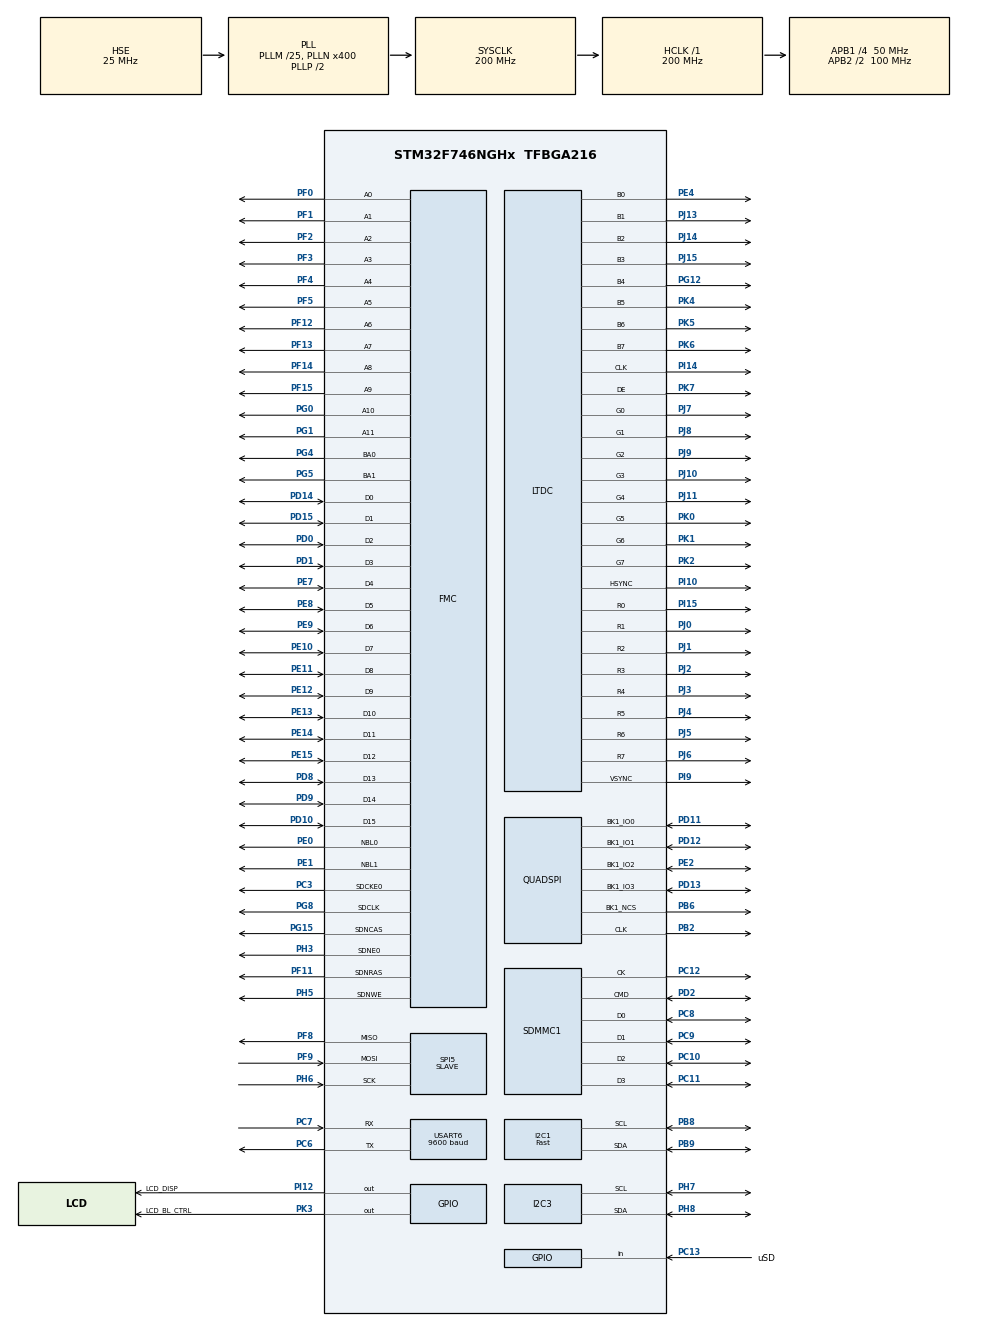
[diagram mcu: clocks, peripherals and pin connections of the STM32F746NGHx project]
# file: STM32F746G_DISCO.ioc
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CORTEX_M7.ART_ACCLERATOR_ENABLE=1
CORTEX_M7.AccessPermission-Cortex_Memory_Protection_Unit_Region0_Settings=MPU_REGION_FULL_ACCESS
CORTEX_M7.AccessPermission-Cortex_Memory_Protection_Unit_Region1_Settings=MPU_REGION_FULL_ACCESS
CORTEX_M7.BaseAddress-Cortex_Memory_Protection_Unit_Region0_Settings=0x00000000
CORTEX_M7.BaseAddress-Cortex_Memory_Protection_Unit_Region1_Settings=0x90000000
CORTEX_M7.CPU_DCache=Enabled
CORTEX_M7.CPU_ICache=Enabled
CORTEX_M7.Enable-Cortex_Memory_Protection_Unit_Region0_Settings=MPU_REGION_ENABLE
CORTEX_M7.Enable-Cortex_Memory_Protection_Unit_Region1_Settings=MPU_REGION_ENABLE
CORTEX_M7.IsCacheable-Cortex_Memory_Protection_Unit_Region1_Settings=MPU_ACCESS_CACHEABLE
CORTEX_M7.MPU_Control=MPU_PRIVILEGED_DEFAULT
CORTEX_M7.PREFETCH_ENABLE=1
CORTEX_M7.Size-Cortex_Memory_Protection_Unit_Region0_Settings=MPU_REGION_SIZE_256MB
CORTEX_M7.Size-Cortex_Memory_Protection_Unit_Region1_Settings=MPU_REGION_SIZE_16MB
Dma.Request0=SDMMC1_RX
Dma.Request1=SDMMC1_TX
Dma.Request2=SPI5_RX
Dma.Request3=USART6_RX
Dma.SDMMC1_RX.0.Direction=DMA_PERIPH_TO_MEMORY
Dma.SDMMC1_RX.0.FIFOMode=DMA_FIFOMODE_ENABLE
Dma.SDMMC1_RX.0.FIFOThreshold=DMA_FIFO_THRESHOLD_FULL
Dma.SDMMC1_RX.0.Instance=DMA2_Stream3
Dma.SDMMC1_RX.0.MemBurst=DMA_MBURST_INC4
Dma.SDMMC1_RX.0.MemDataAlignment=DMA_MDATAALIGN_WORD
Dma.SDMMC1_RX.0.MemInc=DMA_MINC_ENABLE
Dma.SDMMC1_RX.0.Mode=DMA_PFCTRL
Dma.SDMMC1_RX.0.PeriphBurst=DMA_PBURST_INC4
Dma.SDMMC1_RX.0.PeriphDataAlignment=DMA_PDATAALIGN_WORD
Dma.SDMMC1_RX.0.PeriphInc=DMA_PINC_DISABLE
Dma.SDMMC1_RX.0.Priority=DMA_PRIORITY_HIGH
Dma.SDMMC1_TX.1.Direction=DMA_MEMORY_TO_PERIPH
Dma.SDMMC1_TX.1.FIFOMode=DMA_FIFOMODE_ENABLE
Dma.SDMMC1_TX.1.FIFOThreshold=DMA_FIFO_THRESHOLD_FULL
Dma.SDMMC1_TX.1.Instance=DMA2_Stream6
Dma.SDMMC1_TX.1.MemBurst=DMA_MBURST_INC4
Dma.SDMMC1_TX.1.MemDataAlignment=DMA_MDATAALIGN_WORD
Dma.SDMMC1_TX.1.MemInc=DMA_MINC_ENABLE
Dma.SDMMC1_TX.1.Mode=DMA_PFCTRL
Dma.SDMMC1_TX.1.PeriphBurst=DMA_PBURST_INC4
Dma.SDMMC1_TX.1.PeriphDataAlignment=DMA_PDATAALIGN_WORD
Dma.SDMMC1_TX.1.PeriphInc=DMA_PINC_DISABLE
Dma.SDMMC1_TX.1.Priority=DMA_PRIORITY_HIGH
Dma.SPI5_RX.2.Direction=DMA_PERIPH_TO_MEMORY
Dma.SPI5_RX.2.FIFOMode=DMA_FIFOMODE_ENABLE
Dma.SPI5_RX.2.FIFOThreshold=DMA_FIFO_THRESHOLD_FULL
Dma.SPI5_RX.2.Instance=DMA2_Stream5
Dma.SPI5_RX.2.MemBurst=DMA_MBURST_SINGLE
Dma.SPI5_RX.2.MemDataAlignment=DMA_MDATAALIGN_BYTE
Dma.SPI5_RX.2.MemInc=DMA_MINC_ENABLE
Dma.SPI5_RX.2.Mode=DMA_CIRCULAR
Dma.SPI5_RX.2.PeriphBurst=DMA_PBURST_SINGLE
Dma.SPI5_RX.2.PeriphDataAlignment=DMA_PDATAALIGN_BYTE
Dma.SPI5_RX.2.PeriphInc=DMA_PINC_DISABLE
Dma.SPI5_RX.2.Priority=DMA_PRIORITY_LOW
Dma.USART6_RX.3.Direction=DMA_PERIPH_TO_MEMORY
Dma.USART6_RX.3.FIFOMode=DMA_FIFOMODE_ENABLE
Dma.USART6_RX.3.FIFOThreshold=DMA_FIFO_THRESHOLD_FULL
Dma.USART6_RX.3.Instance=DMA2_Stream1
Dma.USART6_RX.3.MemBurst=DMA_MBURST_SINGLE
Dma.USART6_RX.3.MemDataAlignment=DMA_MDATAALIGN_BYTE
Dma.USART6_RX.3.MemInc=DMA_MINC_ENABLE
Dma.USART6_RX.3.Mode=DMA_CIRCULAR
Dma.USART6_RX.3.PeriphBurst=DMA_PBURST_SINGLE
Dma.USART6_RX.3.PeriphDataAlignment=DMA_PDATAALIGN_BYTE
Dma.USART6_RX.3.PeriphInc=DMA_PINC_DISABLE
Dma.USART6_RX.3.Priority=DMA_PRIORITY_VERY_HIGH
FATFS.BSP.number=1
FATFS._MAX_SS=4096
FATFS0.BSP.STBoard=false
FATFS0.BSP.api=Unknown
FATFS0.BSP.instance=PC13
FATFS0.BSP.ip=GPIO
FATFS0.BSP.mode=Input
FATFS0.BSP.name=Detect_SDIO
FATFS0.BSP.solution=PC13
FMC.CASLatency1=FMC_SDRAM_CAS_LATENCY_3
FMC.ExitSelfRefreshDelay1=7
FMC.LoadToActiveDelay1=2
FMC.RCDDelay1=2
FMC.RPDelay1=2
FMC.ReadBurst1=FMC_SDRAM_RBURST_ENABLE
FMC.RowCycleDelay1=7
FMC.SDClockPeriod1=FMC_SDRAM_CLOCK_PERIOD_2
FMC.SelfRefreshTime1=4
FMC.WriteRecoveryTime1=3
FREERTOS.BinarySemaphores01=Uartsem,Static,UartsemControlBlock;SPIsem,Dynamic,NULL;SPIzap,Dynamic,NULL
FREERTOS.HEAP_NUMBER=4
FREERTOS.Mutexes01=myMutex01,Dynamic,NULL
FREERTOS.Tasks01=TouchGFXTask,24,4096,TouchGFX_Task,As weak,NULL,Dynamic,NULL,NULL;defaulttaks2,41,128,StartTask02,Default,NULL,Static,defaulttaks2Buffer,defaulttaks2ControlBlock;myTask03,42,128,StartTask03,Default,NULL,Static,myTask03Buffer,myTask03ControlBlock;UARTprzer,8,128,StartTask04,Default,NULL,Static,TaskDHBuffer,TaskDHControlBlock;TaskBMP,9,128,StartTask05,Default,NULL,Static,TaskBMPBuffer,TaskBMPControlBlock;SprawUART,10,128,StartTask06,Default,NULL,Static,SprawUARTBuffer,SprawUARTControlBlock;SPIprzerw,44,128,StartTask07,Default,NULL,Static,SPIprzerwBuffer,SPIprzerwControlBlock
FREERTOS.configCHECK_FOR_STACK_OVERFLOW=2
FREERTOS.configTOTAL_HEAP_SIZE=32768
FREERTOS.configUSE_APPLICATION_TASK_TAG=1
FREERTOS.configUSE_IDLE_HOOK=1
FREERTOS.configUSE_NEWLIB_REENTRANT=1
I2C1.I2C_Speed_Mode=I2C_Fast
I2C1.Timing=0x00401959
I2C3.Timing=0x00C0EAFF
LTDC.ActiveH=272
LTDC.ActiveW=480
LTDC.Alpha_L0=255
LTDC.FBStartAdress_L0=0xC0000000
LTDC.HBP=13
LTDC.HFP=32
LTDC.HSync=41
LTDC.ImageHeight_L0=272
LTDC.ImageWidth_L0=480
LTDC.Layers=0
LTDC.PixelFormat_L0=LTDC_PIXEL_FORMAT_RGB565
LTDC.VSync=10
LTDC.WindowX1_L0=480
LTDC.WindowY1_L0=272
Mcu.Family=STM32F7
Mcu.Name=STM32F746NGHx
Mcu.Package=TFBGA216
NVIC.DMA2D_IRQn=true\:5\:0\:true\:false\:true\:true\:true\:true\:true
NVIC.DMA2_Stream1_IRQn=true\:5\:0\:false\:false\:true\:true\:false\:true\:true
NVIC.DMA2_Stream3_IRQn=true\:5\:0\:true\:false\:true\:true\:false\:true\:true
NVIC.DMA2_Stream5_IRQn=true\:5\:0\:false\:false\:true\:true\:false\:true\:true
NVIC.DMA2_Stream6_IRQn=true\:5\:0\:true\:false\:true\:true\:false\:true\:true
NVIC.I2C1_ER_IRQn=true\:5\:0\:false\:false\:true\:true\:true\:true\:true
NVIC.I2C1_EV_IRQn=true\:5\:0\:false\:false\:true\:true\:true\:true\:true
NVIC.LTDC_IRQn=true\:5\:0\:true\:false\:true\:true\:true\:true\:true
NVIC.PriorityGroup=NVIC_PRIORITYGROUP_4
NVIC.SDMMC1_IRQn=true\:5\:0\:true\:false\:true\:true\:true\:true\:true
NVIC.SPI5_IRQn=true\:5\:0\:true\:false\:true\:true\:true\:true\:true
NVIC.TIM6_DAC_IRQn=true\:0\:0\:false\:false\:true\:false\:false\:true\:true
NVIC.TIM7_IRQn=true\:5\:0\:true\:false\:true\:true\:true\:true\:true
NVIC.TIM8_TRG_COM_TIM14_IRQn=true\:5\:0\:true\:false\:true\:true\:true\:true\:true
NVIC.TimeBase=TIM6_DAC_IRQn
NVIC.TimeBaseIP=TIM6
NVIC.USART6_IRQn=true\:5\:0\:true\:false\:true\:true\:true\:true\:true
PA13.Mode=Serial_Wire
PA13.Signal=SYS_JTMS-SWDIO
PA14.Mode=Serial_Wire
PA14.Signal=SYS_JTCK-SWCLK
PB2.Mode=Single Bank 1
PB2.Signal=QUADSPI_CLK
PB6.Mode=Single Bank 1
PB6.Signal=QUADSPI_BK1_NCS
PB8.Mode=I2C
PB8.Signal=I2C1_SCL
PB9.Mode=I2C
PB9.Signal=I2C1_SDA
PC10.Mode=SD_4_bits_Wide_bus
PC10.Signal=SDMMC1_D2
PC11.Mode=SD_4_bits_Wide_bus
PC11.Signal=SDMMC1_D3
PC12.Mode=SD_4_bits_Wide_bus
PC12.Signal=SDMMC1_CK
PC13.GPIO_Label=uSD
PC13.GPIO_PuPd=GPIO_NOPULL
PC13.Signal=GPIO_Input
PC3.Mode=SdramChipSelect1_1
PC3.Signal=FMC_SDCKE0
PC6.Mode=Asynchronous
PC6.Signal=USART6_TX
PC7.Mode=Asynchronous
PC7.Signal=USART6_RX
PC8.Mode=SD_4_bits_Wide_bus
PC8.Signal=SDMMC1_D0
PC9.Mode=SD_4_bits_Wide_bus
PC9.Signal=SDMMC1_D1
PD0.Signal=FMC_D2_DA2
PD1.Signal=FMC_D3_DA3
PD10.Signal=FMC_D15_DA15
PD11.Mode=Single Bank 1
PD11.Signal=QUADSPI_BK1_IO0
PD12.Mode=Single Bank 1
PD12.Signal=QUADSPI_BK1_IO1
PD13.Mode=Single Bank 1
PD13.Signal=QUADSPI_BK1_IO3
PD14.Signal=FMC_D0_DA0
PD15.Signal=FMC_D1_DA1
PD2.Mode=SD_4_bits_Wide_bus
PD2.Signal=SDMMC1_CMD
PD8.Signal=FMC_D13_DA13
PD9.Signal=FMC_D14_DA14
PE0.Signal=FMC_NBL0
PE1.Signal=FMC_NBL1
PE10.Signal=FMC_D7_DA7
PE11.Signal=FMC_D8_DA8
PE12.Signal=FMC_D9_DA9
PE13.Signal=FMC_D10_DA10
PE14.Signal=FMC_D11_DA11
PE15.Signal=FMC_D12_DA12
PE2.Mode=Single Bank 1
PE2.Signal=QUADSPI_BK1_IO2
PE4.Mode=RGB888
PE4.Signal=LTDC_B0
PE7.Signal=FMC_D4_DA4
PE8.Signal=FMC_D5_DA5
PE9.Signal=FMC_D6_DA6
PF0.Signal=FMC_A0
PF1.Signal=FMC_A1
PF11.Signal=FMC_SDNRAS
PF12.Signal=FMC_A6
PF13.Signal=FMC_A7
PF14.Signal=FMC_A8
PF15.Signal=FMC_A9
PF2.Signal=FMC_A2
PF3.Signal=FMC_A3
PF4.Signal=FMC_A4
PF5.Signal=FMC_A5
PF8.Mode=Full_Duplex_Slave
PF8.Signal=SPI5_MISO
PF9.Mode=Full_Duplex_Slave
PF9.Signal=SPI5_MOSI
PG0.Signal=FMC_A10
PG1.Signal=FMC_A11
PG12.Mode=RGB888
PG12.Signal=LTDC_B4
PG15.Signal=FMC_SDNCAS
PG4.Signal=FMC_A14_BA0
PG5.Signal=FMC_A15_BA1
PG8.Signal=FMC_SDCLK
PH0/OSC_IN.Mode=HSE-External-Oscillator
PH0/OSC_IN.Signal=RCC_OSC_IN
PH1/OSC_OUT.Mode=HSE-External-Oscillator
PH1/OSC_OUT.Signal=RCC_OSC_OUT
PH3.Mode=SdramChipSelect1_1
PH3.Signal=FMC_SDNE0
PH5.Signal=FMC_SDNWE
PH6.Mode=Full_Duplex_Slave
PH6.Signal=SPI5_SCK
PH7.Mode=I2C
PH7.Signal=I2C3_SCL
PH8.Mode=I2C
PH8.Signal=I2C3_SDA
PI10.Mode=RGB888
PI10.Signal=LTDC_HSYNC
PI12.GPIO_Label=LCD_DISP
PI12.PinState=GPIO_PIN_SET
PI12.Signal=GPIO_Output
PI14.Mode=RGB888
PI14.Signal=LTDC_CLK
PI15.Mode=RGB888
PI15.Signal=LTDC_R0
PI9.Mode=RGB888
PI9.Signal=LTDC_VSYNC
PJ0.Mode=RGB888
PJ0.Signal=LTDC_R1
PJ1.Mode=RGB888
PJ1.Signal=LTDC_R2
PJ10.Mode=RGB888
PJ10.Signal=LTDC_G3
PJ11.Mode=RGB888
PJ11.Signal=LTDC_G4
PJ13.Mode=RGB888
PJ13.Signal=LTDC_B1
PJ14.Mode=RGB888
PJ14.Signal=LTDC_B2
PJ15.Mode=RGB888
PJ15.Signal=LTDC_B3
PJ2.Mode=RGB888
PJ2.Signal=LTDC_R3
PJ3.Mode=RGB888
PJ3.Signal=LTDC_R4
PJ4.Mode=RGB888
PJ4.Signal=LTDC_R5
PJ5.Mode=RGB888
PJ5.Signal=LTDC_R6
PJ6.Mode=RGB888
PJ6.Signal=LTDC_R7
PJ7.Mode=RGB888
PJ7.Signal=LTDC_G0
PJ8.Mode=RGB888
PJ8.Signal=LTDC_G1
PJ9.Mode=RGB888
PJ9.Signal=LTDC_G2
PK0.Mode=RGB888
PK0.Signal=LTDC_G5
PK1.Mode=RGB888
PK1.Signal=LTDC_G6
PK2.Mode=RGB888
PK2.Signal=LTDC_G7
PK3.GPIO_Label=LCD_BL_CTRL
PK3.PinState=GPIO_PIN_SET
PK3.Signal=GPIO_Output
PK4.Mode=RGB888
PK4.Signal=LTDC_B5
PK5.Mode=RGB888
PK5.Signal=LTDC_B6
PK6.Mode=RGB888
PK6.Signal=LTDC_B7
PK7.Mode=RGB888
PK7.Signal=LTDC_DE
ProjectManager.HeapSize=0x400
ProjectManager.StackSize=0x800
ProjectManager.TargetToolchain=STM32CubeIDE
QUADSPI.ChipSelectHighTime=QSPI_CS_HIGH_TIME_6_CYCLE
QUADSPI.ClockPrescaler=1
QUADSPI.FifoThreshold=4
QUADSPI.FlashSize=24
QUADSPI.SampleShifting=QSPI_SAMPLE_SHIFTING_HALFCYCLE
RCC.AHBFreq_Value=200000000
RCC.APB1CLKDivider=RCC_HCLK_DIV4
RCC.APB1Freq_Value=50000000
RCC.APB1TimFreq_Value=100000000
RCC.APB2CLKDivider=RCC_HCLK_DIV2
RCC.APB2Freq_Value=100000000
RCC.APB2TimFreq_Value=200000000
RCC.CortexFreq_Value=200000000
RCC.HCLKFreq_Value=200000000
RCC.HSE_VALUE=25000000
RCC.HSI_VALUE=16000000
RCC.LSE_VALUE=32768
RCC.PLLI2SN=100
RCC.PLLM=25
RCC.PLLN=400
RCC.PLLQ=8
RCC.PLLSAIN=384
RCC.PLLSAIR=5
RCC.PLLSAIRDiv=RCC_PLLSAIDIVR_8
RCC.PLLSourceVirtual=RCC_PLLSOURCE_HSE
RCC.SDMMCClockSelection=RCC_SDMMC1CLKSOURCE_CLK48
RCC.SYSCLKFreq_VALUE=200000000
RCC.SYSCLKSource=RCC_SYSCLKSOURCE_PLLCLK
RCC.USBFreq_Value=50000000
RCC.VCOOutputFreq_Value=400000000
SH.FMC_A0.0=FMC_A0,12b-sda1
SH.FMC_A1.0=FMC_A1,12b-sda1
SH.FMC_A10.0=FMC_A10,12b-sda1
SH.FMC_A11.0=FMC_A11,12b-sda1
SH.FMC_A14_BA0.0=FMC_BA0,FourSdramBanks1
SH.FMC_A15_BA1.0=FMC_BA1,FourSdramBanks1
SH.FMC_A2.0=FMC_A2,12b-sda1
SH.FMC_A3.0=FMC_A3,12b-sda1
SH.FMC_A4.0=FMC_A4,12b-sda1
SH.FMC_A5.0=FMC_A5,12b-sda1
SH.FMC_A6.0=FMC_A6,12b-sda1
SH.FMC_A7.0=FMC_A7,12b-sda1
SH.FMC_A8.0=FMC_A8,12b-sda1
SH.FMC_A9.0=FMC_A9,12b-sda1
SH.FMC_D0_DA0.0=FMC_D0,sd-16b-d1
SH.FMC_D10_DA10.0=FMC_D10,sd-16b-d1
SH.FMC_D11_DA11.0=FMC_D11,sd-16b-d1
SH.FMC_D12_DA12.0=FMC_D12,sd-16b-d1
SH.FMC_D13_DA13.0=FMC_D13,sd-16b-d1
SH.FMC_D14_DA14.0=FMC_D14,sd-16b-d1
SH.FMC_D15_DA15.0=FMC_D15,sd-16b-d1
SH.FMC_D1_DA1.0=FMC_D1,sd-16b-d1
SH.FMC_D2_DA2.0=FMC_D2,sd-16b-d1
SH.FMC_D3_DA3.0=FMC_D3,sd-16b-d1
SH.FMC_D4_DA4.0=FMC_D4,sd-16b-d1
SH.FMC_D5_DA5.0=FMC_D5,sd-16b-d1
SH.FMC_D6_DA6.0=FMC_D6,sd-16b-d1
SH.FMC_D7_DA7.0=FMC_D7,sd-16b-d1
SH.FMC_D8_DA8.0=FMC_D8,sd-16b-d1
SH.FMC_D9_DA9.0=FMC_D9,sd-16b-d1
SH.FMC_NBL0.0=FMC_NBL0,Sd2ByteEnable1
SH.FMC_NBL1.0=FMC_NBL1,Sd2ByteEnable1
SH.FMC_SDCLK.0=FMC_SDCLK,12b-sda1
SH.FMC_SDNCAS.0=FMC_SDNCAS,12b-sda1
SH.FMC_SDNRAS.0=FMC_SDNRAS,12b-sda1
SH.FMC_SDNWE.0=FMC_SDNWE,12b-sda1
SPI5.DataSize=SPI_DATASIZE_8BIT
SPI5.Direction=SPI_DIRECTION_2LINES
SPI5.Mode=SPI_MODE_SLAVE
SPI5.VirtualType=VM_SLAVE
STMicroelectronics.X-CUBE-TOUCHGFX.4.21.0.ApplicationCcGraphicsJjApplication=TouchGFXOoGenerator
STMicroelectronics.X-CUBE-TOUCHGFX.4.21.0.tgfx_address1=0xC0000000
STMicroelectronics.X-CUBE-TOUCHGFX.4.21.0.tgfx_address2=0xC003FC00
STMicroelectronics.X-CUBE-TOUCHGFX.4.21.0.tgfx_buffering_strategy=Double
STMicroelectronics.X-CUBE-TOUCHGFX.4.21.0.tgfx_display_interface=disp_ltdc
STMicroelectronics.X-CUBE-TOUCHGFX.4.21.0.tgfx_hardware_accelerator=dma_2d
STMicroelectronics.X-CUBE-TOUCHGFX.4.21.0.tgfx_location=By Address
STMicroelectronics.X-CUBE-TOUCHGFX.4.21.0.tgfx_vsync=vsync_ltdc
TIM14.Period=40000
TIM14.Prescaler=9999
TIM7.Period=60000
TIM7.Prescaler=99
USART6.BaudRate=9600
USART6.VirtualMode-Asynchronous=VM_ASYNC
VP_CRC_VS_CRC.Mode=CRC_Activate
VP_DMA2D_VS_DMA2D.Mode=DMA2D_Activate
VP_FATFS_VS_SDIO.Mode=SDIO
VP_FREERTOS_VS_CMSIS_V2.Mode=CMSIS_V2
VP_RTC_VS_RTC_Activate.Mode=RTC_Enabled
VP_RTC_VS_RTC_Calendar.Mode=RTC_Calendar
VP_STMicroelectronics.X-CUBE-TOUCHGFX_VS_GraphicsJjApplication_4.21.0.Mode=GraphicsJjApplication
VP_SYS_VS_tim6.Mode=TIM6
VP_TIM14_VS_ClockSourceINT.Mode=Enable_Timer
VP_TIM7_VS_ClockSourceINT.Mode=Enable_Timer
board=custom

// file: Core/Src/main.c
/* USER CODE BEGIN Header */
/**
  ******************************************************************************
  * @file           : main.c
  * @brief          : Main program body
  ******************************************************************************
  * @attention
  *
  * <h2><center>&copy; Copyright (c) 2020 STMicroelectronics.
  * All rights reserved.</center></h2>
  *
  * This software component is licensed by ST under Ultimate Liberty license
  * SLA0044, the "License"; You may not use this file except in compliance with
  * the License. You may obtain a copy of the License at:
  *                             www.st.com/SLA0044
  *
  ******************************************************************************
  */
/* USER CODE END Header */
#include "main.h"
#include "cmsis_os.h"
#include "fatfs.h"
#include "app_touchgfx.h"

/* USER CODE BEGIN Includes */
#include <stm32746g_discovery_qspi.h>
#include <string.h>
#include <stdio.h>

#include "mpu6050.h"
#include "BMPXX80.h"
#include "DHT.h"
/* USER CODE END Includes */

typedef StaticTask_t osStaticThreadDef_t;
typedef StaticSemaphore_t osStaticSemaphoreDef_t;
/* USER CODE BEGIN PTD */
DHT_DataTypedef DHT11_Data;
MPU6050_t MPU6050;
RTC_TimeTypeDef RtcTime;
RTC_DateTypeDef RtcDate;
#define SPIbufor 8160
#define GPSbufor 1000
/* USER CODE END PTD */

/* USER CODE BEGIN PD */

#define REFRESH_COUNT        1835

#define SDRAM_TIMEOUT                            ((uint32_t)0xFFFF)
#define SDRAM_MODEREG_BURST_LENGTH_1             ((uint16_t)0x0000)
#define SDRAM_MODEREG_BURST_LENGTH_2             ((uint16_t)0x0001)
#define SDRAM_MODEREG_BURST_LENGTH_4             ((uint16_t)0x0002)
#define SDRAM_MODEREG_BURST_LENGTH_8             ((uint16_t)0x0004)
#define SDRAM_MODEREG_BURST_TYPE_SEQUENTIAL      ((uint16_t)0x0000)
#define SDRAM_MODEREG_BURST_TYPE_INTERLEAVED     ((uint16_t)0x0008)
#define SDRAM_MODEREG_CAS_LATENCY_2              ((uint16_t)0x0020)
#define SDRAM_MODEREG_CAS_LATENCY_3              ((uint16_t)0x0030)
#define SDRAM_MODEREG_OPERATING_MODE_STANDARD    ((uint16_t)0x0000)
#define SDRAM_MODEREG_WRITEBURST_MODE_PROGRAMMED ((uint16_t)0x0000)
#define SDRAM_MODEREG_WRITEBURST_MODE_SINGLE     ((uint16_t)0x0200)

/* USER CODE END PD */

CRC_HandleTypeDef hcrc;

DMA2D_HandleTypeDef hdma2d;

I2C_HandleTypeDef hi2c1;
I2C_HandleTypeDef hi2c3;

LTDC_HandleTypeDef hltdc;

QSPI_HandleTypeDef hqspi;

RTC_HandleTypeDef hrtc;

SD_HandleTypeDef hsd1;
DMA_HandleTypeDef hdma_sdmmc1_rx;
DMA_HandleTypeDef hdma_sdmmc1_tx;

SPI_HandleTypeDef hspi5;
DMA_HandleTypeDef hdma_spi5_rx;

TIM_HandleTypeDef htim7;
TIM_HandleTypeDef htim14;

UART_HandleTypeDef huart6;
DMA_HandleTypeDef hdma_usart6_rx;

SDRAM_HandleTypeDef hsdram1;

/* Definitions for TouchGFXTask */
osThreadId_t TouchGFXTaskHandle;
const osThreadAttr_t TouchGFXTask_attributes = {
  .name = "TouchGFXTask",
  .priority = (osPriority_t) osPriorityNormal,
  .stack_size = 4096 * 4
};
/* Definitions for defaulttaks2 */
osThreadId_t defaulttaks2Handle;
uint32_t defaulttaks2Buffer[ 128 ];
osStaticThreadDef_t defaulttaks2ControlBlock;
const osThreadAttr_t defaulttaks2_attributes = {
  .name = "defaulttaks2",
  .stack_mem = &defaulttaks2Buffer[0],
  .stack_size = sizeof(defaulttaks2Buffer),
  .cb_mem = &defaulttaks2ControlBlock,
  .cb_size = sizeof(defaulttaks2ControlBlock),
  .priority = (osPriority_t) osPriorityHigh1,
};
/* Definitions for myTask03 */
osThreadId_t myTask03Handle;
uint32_t myTask03Buffer[ 128 ];
osStaticThreadDef_t myTask03ControlBlock;
const osThreadAttr_t myTask03_attributes = {
  .name = "myTask03",
  .stack_mem = &myTask03Buffer[0],
  .stack_size = sizeof(myTask03Buffer),
  .cb_mem = &myTask03ControlBlock,
  .cb_size = sizeof(myTask03ControlBlock),
  .priority = (osPriority_t) osPriorityHigh2,
};
/* Definitions for UARTprzer */
osThreadId_t UARTprzerHandle;
uint32_t TaskDHBuffer[ 128 ];
osStaticThreadDef_t TaskDHControlBlock;
const osThreadAttr_t UARTprzer_attributes = {
  .name = "UARTprzer",
  .stack_mem = &TaskDHBuffer[0],
  .stack_size = sizeof(TaskDHBuffer),
  .cb_mem = &TaskDHControlBlock,
  .cb_size = sizeof(TaskDHControlBlock),
  .priority = (osPriority_t) osPriorityLow,
};
/* Definitions for TaskBMP */
osThreadId_t TaskBMPHandle;
uint32_t TaskBMPBuffer[ 128 ];
osStaticThreadDef_t TaskBMPControlBlock;
const osThreadAttr_t TaskBMP_attributes = {
  .name = "TaskBMP",
  .stack_mem = &TaskBMPBuffer[0],
  .stack_size = sizeof(TaskBMPBuffer),
  .cb_mem = &TaskBMPControlBlock,
  .cb_size = sizeof(TaskBMPControlBlock),
  .priority = (osPriority_t) osPriorityLow1,
};
/* Definitions for SprawUART */
osThreadId_t SprawUARTHandle;
uint32_t SprawUARTBuffer[ 128 ];
osStaticThreadDef_t SprawUARTControlBlock;
const osThreadAttr_t SprawUART_attributes = {
  .name = "SprawUART",
  .stack_mem = &SprawUARTBuffer[0],
  .stack_size = sizeof(SprawUARTBuffer),
  .cb_mem = &SprawUARTControlBlock,
  .cb_size = sizeof(SprawUARTControlBlock),
  .priority = (osPriority_t) osPriorityLow2,
};
/* Definitions for SPIprzerw */
osThreadId_t SPIprzerwHandle;
uint32_t SPIprzerwBuffer[ 128 ];
osStaticThreadDef_t SPIprzerwControlBlock;
const osThreadAttr_t SPIprzerw_attributes = {
  .name = "SPIprzerw",
  .stack_mem = &SPIprzerwBuffer[0],
  .stack_size = sizeof(SPIprzerwBuffer),
  .cb_mem = &SPIprzerwControlBlock,
  .cb_size = sizeof(SPIprzerwControlBlock),
  .priority = (osPriority_t) osPriorityHigh4,
};
/* Definitions for myMutex01 */
osMutexId_t myMutex01Handle;
const osMutexAttr_t myMutex01_attributes = {
  .name = "myMutex01"
};
/* Definitions for Uartsem */
osSemaphoreId_t UartsemHandle;
osStaticSemaphoreDef_t UartsemControlBlock;
const osSemaphoreAttr_t Uartsem_attributes = {
  .name = "Uartsem",
  .cb_mem = &UartsemControlBlock,
  .cb_size = sizeof(UartsemControlBlock),
};
/* Definitions for SPIsem */
osSemaphoreId_t SPIsemHandle;
const osSemaphoreAttr_t SPIsem_attributes = {
  .name = "SPIsem"
};
/* Definitions for SPIzap */
osSemaphoreId_t SPIzapHandle;
const osSemaphoreAttr_t SPIzap_attributes = {
  .name = "SPIzap"
};
/* USER CODE BEGIN PV */
static FMC_SDRAM_CommandTypeDef Command;

/* USER CODE END PV */

void SystemClock_Config(void);
static void MPU_Config(void);
static void MX_GPIO_Init(void);
static void MX_DMA_Init(void);
static void MX_DMA2D_Init(void);
static void MX_FMC_Init(void);
static void MX_I2C3_Init(void);
static void MX_LTDC_Init(void);
static void MX_QUADSPI_Init(void);
static void MX_SDMMC1_SD_Init(void);
static void MX_CRC_Init(void);
static void MX_TIM7_Init(void);
static void MX_I2C1_Init(void);
static void MX_SPI5_Init(void);
static void MX_TIM14_Init(void);
static void MX_RTC_Init(void);
static void MX_USART6_UART_Init(void);
void TouchGFX_Task(void *argument);
void StartTask02(void *argument);
void StartTask03(void *argument);
void StartTask04(void *argument);
void StartTask05(void *argument);
void StartTask06(void *argument);
void StartTask07(void *argument);

/* USER CODE BEGIN 0 */

/*Deklaracja funkcji odpowiedzialnej za odliczanie mikrosekund*/
void Delay_us (uint16_t us)
{
	__HAL_TIM_SET_COUNTER(&htim7,0);  // set the counter value a 0
	while ((__HAL_TIM_GET_COUNTER(&htim7)) < us);  // wait for the counter to reach the us input in the parameter
}

/*bufor do odbioru danych z kanału UART*/
uint8_t Received[GPSbufor] ;
/*kopia bufor do odbioru danych z kanału UART*/
uint8_t Received2[GPSbufor] ;
/*bufor dla danych o czasie zczytania danych*/
uint8_t Message[50];
/*bufor do odbioru danych z kanału SPI*/
uint8_t Received4[SPIbufor] ;
/*kopia bufora do odbioru danych z kanału SPI*/
uint8_t Received431[SPIbufor] ;
uint16_t Milliseconds;
/*kontrola wykonania polecenia {przerwanie_IT, przyrównanie do przerwania, iteracja co zaspis} dla SPI */
uint16_t asdUART1[3]={0,0,0};
/*kontrola wykonania polecenia {przerwanie_IT, przyrównanie do przerwania, iteracja co zaspis} dla UART */
uint16_t asdGPS[3]={0,0,0};
/*kontrola wykonania polecenia {przerwanie timera, iteracja co próbe zapisu , iteracja co kolejny pakiet bufora} dla SPI */
uint16_t asdCZUJNIKI[3]={0,0,0};
float TempDH, WilgDH;
float TempBMP;
int32_t CisnBMP;
/*zmienne do konwersji*/
int32_t  dod1;
int32_t  dod2;
int32_t  dod3;
int awaria=0;
/*bufor przechowujący dane do zapisu z czujników*/
char buffer[200][110];
/*licznik zapełnienia bufora*/
int licznik4=0;
int pomuart =0;

FRESULT res;
uint32_t byteswritten; /* licznik zapisanych danych */
/*zmienne odpowiedzialne za kontrole włączenia/wyłączenia zapisu */
int8_t zapisekran=0;
int8_t zapisdzial=0;

/* USER CODE END 0 */

int main(void)
{

  /* MPU Configuration--------------------------------------------------------*/
  MPU_Config();

  /* Enable I-Cache---------------------------------------------------------*/
  SCB_EnableICache();

  /* Enable D-Cache---------------------------------------------------------*/
  SCB_EnableDCache();

  /* MCU Configuration--------------------------------------------------------*/

  /* Reset of all peripherals, Initializes the Flash interface and the Systick. */
  HAL_Init();

  /* Configure the system clock */
  SystemClock_Config();

  /* Initialize all configured peripherals */
  MX_GPIO_Init();
  MX_DMA_Init();
  MX_DMA2D_Init();
  MX_FMC_Init();
  MX_I2C3_Init();
  MX_LTDC_Init();
  MX_QUADSPI_Init();
  MX_SDMMC1_SD_Init();
  MX_CRC_Init();
  MX_FATFS_Init();
  MX_TIM7_Init();
  MX_I2C1_Init();
  MX_SPI5_Init();
  MX_TIM14_Init();
  MX_RTC_Init();
  MX_USART6_UART_Init();
  MX_TouchGFX_Init();
  /* USER CODE BEGIN 2 */
  /* Call PreOsInit function */
  MX_TouchGFX_PreOSInit();

/*Inicjacja zegara odpowiedzialnego za liczenie mileskund */
  HAL_TIM_Base_Start_IT(&htim7);
  /*Inicjacja ustawień dla czujników */
  MPU6050_Init(&hi2c1, 1, 1, 5);
  MPU6050_Bypass(&hi2c1);
  HMC5883L_Setup(&hi2c1);
  MPU6050_Master(&hi2c1);
  MPU6050_Slave_Read(&hi2c1);
  BMP180_Init(&hi2c1,BMP180_STANDARD);

  /* USER CODE END 2 */

  /* Init scheduler */
  osKernelInitialize();
  /* Create the mutex(es) */
  /* creation of myMutex01 */
  myMutex01Handle = osMutexNew(&myMutex01_attributes);

  /* Create the semaphores(s) */
  /* creation of Uartsem */
  UartsemHandle = osSemaphoreNew(1, 1, &Uartsem_attributes);

  /* creation of SPIsem */
  SPIsemHandle = osSemaphoreNew(1, 1, &SPIsem_attributes);

  /* creation of SPIzap */
  SPIzapHandle = osSemaphoreNew(1, 1, &SPIzap_attributes);

  /* Create the thread(s) */
  /* creation of TouchGFXTask */
  TouchGFXTaskHandle = osThreadNew(TouchGFX_Task, NULL, &TouchGFXTask_attributes);

  /* creation of defaulttaks2 */
  defaulttaks2Handle = osThreadNew(StartTask02, NULL, &defaulttaks2_attributes);

  /* creation of myTask03 */
  myTask03Handle = osThreadNew(StartTask03, NULL, &myTask03_attributes);

  /* creation of UARTprzer */
  UARTprzerHandle = osThreadNew(StartTask04, NULL, &UARTprzer_attributes);

  /* creation of TaskBMP */
  TaskBMPHandle = osThreadNew(StartTask05, NULL, &TaskBMP_attributes);

  /* creation of SprawUART */
  SprawUARTHandle = osThreadNew(StartTask06, NULL, &SprawUART_attributes);

  /* creation of SPIprzerw */
  SPIprzerwHandle = osThreadNew(StartTask07, NULL, &SPIprzerw_attributes);

  /* Start scheduler */
  osKernelStart();

  /* We should never get here as control is now taken by the scheduler */
  /* Infinite loop */
  while (1)
  {

  }
}

void SystemClock_Config(void)
{
  RCC_OscInitTypeDef RCC_OscInitStruct = {0};
  RCC_ClkInitTypeDef RCC_ClkInitStruct = {0};
  RCC_PeriphCLKInitTypeDef PeriphClkInitStruct = {0};

  /** Configure the main internal regulator output voltage
  */
  __HAL_RCC_PWR_CLK_ENABLE();
  __HAL_PWR_VOLTAGESCALING_CONFIG(PWR_REGULATOR_VOLTAGE_SCALE1);
  /** Initializes the RCC Oscillators according to the specified parameters
  * in the RCC_OscInitTypeDef structure.
  */
  RCC_OscInitStruct.OscillatorType = RCC_OSCILLATORTYPE_LSI|RCC_OSCILLATORTYPE_HSE;
  RCC_OscInitStruct.HSEState = RCC_HSE_ON;
  RCC_OscInitStruct.LSIState = RCC_LSI_ON;
  RCC_OscInitStruct.PLL.PLLState = RCC_PLL_ON;
  RCC_OscInitStruct.PLL.PLLSource = RCC_PLLSOURCE_HSE;
  RCC_OscInitStruct.PLL.PLLM = 25;
  RCC_OscInitStruct.PLL.PLLN = 400;
  RCC_OscInitStruct.PLL.PLLP = RCC_PLLP_DIV2;
  RCC_OscInitStruct.PLL.PLLQ = 8;
  if (HAL_RCC_OscConfig(&RCC_OscInitStruct) != HAL_OK)
  {
    Error_Handler();
  }
  /** Activate the Over-Drive mode
  */
  if (HAL_PWREx_EnableOverDrive() != HAL_OK)
  {
    Error_Handler();
  }
  /** Initializes the CPU, AHB and APB buses clocks
  */
  RCC_ClkInitStruct.ClockType = RCC_CLOCKTYPE_HCLK|RCC_CLOCKTYPE_SYSCLK
                              |RCC_CLOCKTYPE_PCLK1|RCC_CLOCKTYPE_PCLK2;
  RCC_ClkInitStruct.SYSCLKSource = RCC_SYSCLKSOURCE_PLLCLK;
  RCC_ClkInitStruct.AHBCLKDivider = RCC_SYSCLK_DIV1;
  RCC_ClkInitStruct.APB1CLKDivider = RCC_HCLK_DIV4;
  RCC_ClkInitStruct.APB2CLKDivider = RCC_HCLK_DIV2;

  if (HAL_RCC_ClockConfig(&RCC_ClkInitStruct, FLASH_LATENCY_6) != HAL_OK)
  {
    Error_Handler();
  }
  PeriphClkInitStruct.PeriphClockSelection = RCC_PERIPHCLK_LTDC|RCC_PERIPHCLK_RTC
                              |RCC_PERIPHCLK_USART6|RCC_PERIPHCLK_I2C1
                              |RCC_PERIPHCLK_I2C3|RCC_PERIPHCLK_SDMMC1
                              |RCC_PERIPHCLK_CLK48;
  PeriphClkInitStruct.PLLSAI.PLLSAIN = 384;
  PeriphClkInitStruct.PLLSAI.PLLSAIR = 5;
  PeriphClkInitStruct.PLLSAI.PLLSAIQ = 2;
  PeriphClkInitStruct.PLLSAI.PLLSAIP = RCC_PLLSAIP_DIV2;
  PeriphClkInitStruct.PLLSAIDivQ = 1;
  PeriphClkInitStruct.PLLSAIDivR = RCC_PLLSAIDIVR_8;
  PeriphClkInitStruct.RTCClockSelection = RCC_RTCCLKSOURCE_LSI;
  PeriphClkInitStruct.Usart6ClockSelection = RCC_USART6CLKSOURCE_PCLK2;
  PeriphClkInitStruct.I2c1ClockSelection = RCC_I2C1CLKSOURCE_PCLK1;
  PeriphClkInitStruct.I2c3ClockSelection = RCC_I2C3CLKSOURCE_PCLK1;
  PeriphClkInitStruct.Clk48ClockSelection = RCC_CLK48SOURCE_PLL;
  PeriphClkInitStruct.Sdmmc1ClockSelection = RCC_SDMMC1CLKSOURCE_CLK48;
  if (HAL_RCCEx_PeriphCLKConfig(&PeriphClkInitStruct) != HAL_OK)
  {
    Error_Handler();
  }
}

static void MX_CRC_Init(void)
{

  hcrc.Instance = CRC;
  hcrc.Init.DefaultPolynomialUse = DEFAULT_POLYNOMIAL_ENABLE;
  hcrc.Init.DefaultInitValueUse = DEFAULT_INIT_VALUE_ENABLE;
  hcrc.Init.InputDataInversionMode = CRC_INPUTDATA_INVERSION_NONE;
  hcrc.Init.OutputDataInversionMode = CRC_OUTPUTDATA_INVERSION_DISABLE;
  hcrc.InputDataFormat = CRC_INPUTDATA_FORMAT_BYTES;
  if (HAL_CRC_Init(&hcrc) != HAL_OK)
  {
    Error_Handler();
  }

}

static void MX_DMA2D_Init(void)
{

  hdma2d.Instance = DMA2D;
  hdma2d.Init.Mode = DMA2D_M2M;
  hdma2d.Init.ColorMode = DMA2D_OUTPUT_ARGB8888;
  hdma2d.Init.OutputOffset = 0;
  hdma2d.LayerCfg[1].InputOffset = 0;
  hdma2d.LayerCfg[1].InputColorMode = DMA2D_INPUT_ARGB8888;
  hdma2d.LayerCfg[1].AlphaMode = DMA2D_NO_MODIF_ALPHA;
  hdma2d.LayerCfg[1].InputAlpha = 0;
  if (HAL_DMA2D_Init(&hdma2d) != HAL_OK)
  {
    Error_Handler();
  }
  if (HAL_DMA2D_ConfigLayer(&hdma2d, 1) != HAL_OK)
  {
    Error_Handler();
  }

}

static void MX_I2C1_Init(void)
{

  hi2c1.Instance = I2C1;
  hi2c1.Init.Timing = 0x00401959;
  hi2c1.Init.OwnAddress1 = 0;
  hi2c1.Init.AddressingMode = I2C_ADDRESSINGMODE_7BIT;
  hi2c1.Init.DualAddressMode = I2C_DUALADDRESS_DISABLE;
  hi2c1.Init.OwnAddress2 = 0;
  hi2c1.Init.OwnAddress2Masks = I2C_OA2_NOMASK;
  hi2c1.Init.GeneralCallMode = I2C_GENERALCALL_DISABLE;
  hi2c1.Init.NoStretchMode = I2C_NOSTRETCH_DISABLE;
  if (HAL_I2C_Init(&hi2c1) != HAL_OK)
  {
    Error_Handler();
  }
  /** Configure Analogue filter
  */
  if (HAL_I2CEx_ConfigAnalogFilter(&hi2c1, I2C_ANALOGFILTER_ENABLE) != HAL_OK)
  {
    Error_Handler();
  }
  /** Configure Digital filter
  */
  if (HAL_I2CEx_ConfigDigitalFilter(&hi2c1, 0) != HAL_OK)
  {
    Error_Handler();
  }

}

static void MX_I2C3_Init(void)
{

  hi2c3.Instance = I2C3;
  hi2c3.Init.Timing = 0x00C0EAFF;
  hi2c3.Init.OwnAddress1 = 0;
  hi2c3.Init.AddressingMode = I2C_ADDRESSINGMODE_7BIT;
  hi2c3.Init.DualAddressMode = I2C_DUALADDRESS_DISABLE;
  hi2c3.Init.OwnAddress2 = 0;
  hi2c3.Init.OwnAddress2Masks = I2C_OA2_NOMASK;
  hi2c3.Init.GeneralCallMode = I2C_GENERALCALL_DISABLE;
  hi2c3.Init.NoStretchMode = I2C_NOSTRETCH_DISABLE;
  if (HAL_I2C_Init(&hi2c3) != HAL_OK)
  {
    Error_Handler();
  }
  /** Configure Analogue filter
  */
  if (HAL_I2CEx_ConfigAnalogFilter(&hi2c3, I2C_ANALOGFILTER_ENABLE) != HAL_OK)
  {
    Error_Handler();
  }
  /** Configure Digital filter
  */
  if (HAL_I2CEx_ConfigDigitalFilter(&hi2c3, 0) != HAL_OK)
  {
    Error_Handler();
  }

}

static void MX_LTDC_Init(void)
{

  LTDC_LayerCfgTypeDef pLayerCfg = {0};

  hltdc.Instance = LTDC;
  hltdc.Init.HSPolarity = LTDC_HSPOLARITY_AL;
  hltdc.Init.VSPolarity = LTDC_VSPOLARITY_AL;
  hltdc.Init.DEPolarity = LTDC_DEPOLARITY_AL;
  hltdc.Init.PCPolarity = LTDC_PCPOLARITY_IPC;
  hltdc.Init.HorizontalSync = 40;
  hltdc.Init.VerticalSync = 9;
  hltdc.Init.AccumulatedHBP = 53;
  hltdc.Init.AccumulatedVBP = 11;
  hltdc.Init.AccumulatedActiveW = 533;
  hltdc.Init.AccumulatedActiveH = 283;
  hltdc.Init.TotalWidth = 565;
  hltdc.Init.TotalHeigh = 285;
  hltdc.Init.Backcolor.Blue = 0;
  hltdc.Init.Backcolor.Green = 0;
  hltdc.Init.Backcolor.Red = 0;
  if (HAL_LTDC_Init(&hltdc) != HAL_OK)
  {
    Error_Handler();
  }
  pLayerCfg.WindowX0 = 0;
  pLayerCfg.WindowX1 = 480;
  pLayerCfg.WindowY0 = 0;
  pLayerCfg.WindowY1 = 272;
  pLayerCfg.PixelFormat = LTDC_PIXEL_FORMAT_RGB565;
  pLayerCfg.Alpha = 255;
  pLayerCfg.Alpha0 = 0;
  pLayerCfg.BlendingFactor1 = LTDC_BLENDING_FACTOR1_CA;
  pLayerCfg.BlendingFactor2 = LTDC_BLENDING_FACTOR2_CA;
  pLayerCfg.FBStartAdress = 0xC0000000;
  pLayerCfg.ImageWidth = 480;
  pLayerCfg.ImageHeight = 272;
  pLayerCfg.Backcolor.Blue = 0;
  pLayerCfg.Backcolor.Green = 0;
  pLayerCfg.Backcolor.Red = 0;
  if (HAL_LTDC_ConfigLayer(&hltdc, &pLayerCfg, 0) != HAL_OK)
  {
    Error_Handler();
  }

}

static void MX_QUADSPI_Init(void)
{

  /* QUADSPI parameter configuration*/
  hqspi.Instance = QUADSPI;
  hqspi.Init.ClockPrescaler = 1;
  hqspi.Init.FifoThreshold = 4;
  hqspi.Init.SampleShifting = QSPI_SAMPLE_SHIFTING_HALFCYCLE;
  hqspi.Init.FlashSize = 24;
  hqspi.Init.ChipSelectHighTime = QSPI_CS_HIGH_TIME_6_CYCLE;
  hqspi.Init.ClockMode = QSPI_CLOCK_MODE_0;
  hqspi.Init.FlashID = QSPI_FLASH_ID_1;
  hqspi.Init.DualFlash = QSPI_DUALFLASH_DISABLE;
  if (HAL_QSPI_Init(&hqspi) != HAL_OK)
  {
    Error_Handler();
  }
  /* USER CODE BEGIN QUADSPI_Init 2 */
  BSP_QSPI_Init();

  BSP_QSPI_MemoryMappedMode();
  HAL_NVIC_DisableIRQ(QUADSPI_IRQn);
  /* USER CODE END QUADSPI_Init 2 */

}

static void MX_RTC_Init(void)
{

  RTC_TimeTypeDef sTime = {0};
  RTC_DateTypeDef sDate = {0};

  /** Initialize RTC Only
  */
  hrtc.Instance = RTC;
  hrtc.Init.HourFormat = RTC_HOURFORMAT_24;
  hrtc.Init.AsynchPrediv = 127;
  hrtc.Init.SynchPrediv = 255;
  hrtc.Init.OutPut = RTC_OUTPUT_DISABLE;
  hrtc.Init.OutPutPolarity = RTC_OUTPUT_POLARITY_HIGH;
  hrtc.Init.OutPutType = RTC_OUTPUT_TYPE_OPENDRAIN;
  if (HAL_RTC_Init(&hrtc) != HAL_OK)
  {
    Error_Handler();
  }

  /** Initialize RTC and set the Time and Date
  */
  sTime.Hours = 0x0;
  sTime.Minutes = 0x0;
  sTime.Seconds = 0x0;
  sTime.DayLightSaving = RTC_DAYLIGHTSAVING_NONE;
  sTime.StoreOperation = RTC_STOREOPERATION_RESET;
  if (HAL_RTC_SetTime(&hrtc, &sTime, RTC_FORMAT_BCD) != HAL_OK)
  {
    Error_Handler();
  }
  sDate.WeekDay = RTC_WEEKDAY_MONDAY;
  sDate.Month = RTC_MONTH_JANUARY;
  sDate.Date = 0x1;
  sDate.Year = 0x0;

  if (HAL_RTC_SetDate(&hrtc, &sDate, RTC_FORMAT_BCD) != HAL_OK)
  {
    Error_Handler();
  }

}

static void MX_SDMMC1_SD_Init(void)
{

  hsd1.Instance = SDMMC1;
  hsd1.Init.ClockEdge = SDMMC_CLOCK_EDGE_RISING;
  hsd1.Init.ClockBypass = SDMMC_CLOCK_BYPASS_DISABLE;
  hsd1.Init.ClockPowerSave = SDMMC_CLOCK_POWER_SAVE_DISABLE;
  hsd1.Init.BusWide = SDMMC_BUS_WIDE_1B;
  hsd1.Init.HardwareFlowControl = SDMMC_HARDWARE_FLOW_CONTROL_DISABLE;
  hsd1.Init.ClockDiv = 0;

}

static void MX_SPI5_Init(void)
{

  /* SPI5 parameter configuration*/
  hspi5.Instance = SPI5;
  hspi5.Init.Mode = SPI_MODE_SLAVE;
  hspi5.Init.Direction = SPI_DIRECTION_2LINES;
  hspi5.Init.DataSize = SPI_DATASIZE_8BIT;
  hspi5.Init.CLKPolarity = SPI_POLARITY_LOW;
  hspi5.Init.CLKPhase = SPI_PHASE_1EDGE;
  hspi5.Init.NSS = SPI_NSS_SOFT;
  hspi5.Init.FirstBit = SPI_FIRSTBIT_MSB;
  hspi5.Init.TIMode = SPI_TIMODE_DISABLE;
  hspi5.Init.CRCCalculation = SPI_CRCCALCULATION_DISABLE;
  hspi5.Init.CRCPolynomial = 7;
  hspi5.Init.CRCLength = SPI_CRC_LENGTH_DATASIZE;
  hspi5.Init.NSSPMode = SPI_NSS_PULSE_DISABLE;
  if (HAL_SPI_Init(&hspi5) != HAL_OK)
  {
    Error_Handler();
  }

}

static void MX_TIM7_Init(void)
{

  TIM_MasterConfigTypeDef sMasterConfig = {0};

  htim7.Instance = TIM7;
  htim7.Init.Prescaler = 99;
  htim7.Init.CounterMode = TIM_COUNTERMODE_UP;
  htim7.Init.Period = 60000;
  htim7.Init.AutoReloadPreload = TIM_AUTORELOAD_PRELOAD_DISABLE;
  if (HAL_TIM_Base_Init(&htim7) != HAL_OK)
  {
    Error_Handler();
  }
  sMasterConfig.MasterOutputTrigger = TIM_TRGO_RESET;
  sMasterConfig.MasterSlaveMode = TIM_MASTERSLAVEMODE_DISABLE;
  if (HAL_TIMEx_MasterConfigSynchronization(&htim7, &sMasterConfig) != HAL_OK)
  {
    Error_Handler();
  }

}

static void MX_TIM14_Init(void)
{

  htim14.Instance = TIM14;
  htim14.Init.Prescaler = 9999;
  htim14.Init.CounterMode = TIM_COUNTERMODE_UP;
  htim14.Init.Period = 40000;
  htim14.Init.ClockDivision = TIM_CLOCKDIVISION_DIV1;
  htim14.Init.AutoReloadPreload = TIM_AUTORELOAD_PRELOAD_DISABLE;
  if (HAL_TIM_Base_Init(&htim14) != HAL_OK)
  {
    Error_Handler();
  }

}

static void MX_USART6_UART_Init(void)
{

  huart6.Instance = USART6;
  huart6.Init.BaudRate = 9600;
  huart6.Init.WordLength = UART_WORDLENGTH_8B;
  huart6.Init.StopBits = UART_STOPBITS_1;
  huart6.Init.Parity = UART_PARITY_NONE;
  huart6.Init.Mode = UART_MODE_TX_RX;
  huart6.Init.HwFlowCtl = UART_HWCONTROL_NONE;
  huart6.Init.OverSampling = UART_OVERSAMPLING_16;
  huart6.Init.OneBitSampling = UART_ONE_BIT_SAMPLE_DISABLE;
  huart6.AdvancedInit.AdvFeatureInit = UART_ADVFEATURE_NO_INIT;
  if (HAL_UART_Init(&huart6) != HAL_OK)
  {
    Error_Handler();
  }

}

static void MX_DMA_Init(void)
{

  /* DMA controller clock enable */
  __HAL_RCC_DMA2_CLK_ENABLE();

  /* DMA interrupt init */
  /* DMA2_Stream1_IRQn interrupt configuration */
  HAL_NVIC_SetPriority(DMA2_Stream1_IRQn, 5, 0);
  HAL_NVIC_EnableIRQ(DMA2_Stream1_IRQn);
  /* DMA2_Stream3_IRQn interrupt configuration */
  HAL_NVIC_SetPriority(DMA2_Stream3_IRQn, 5, 0);
  HAL_NVIC_EnableIRQ(DMA2_Stream3_IRQn);
  /* DMA2_Stream5_IRQn interrupt configuration */
  HAL_NVIC_SetPriority(DMA2_Stream5_IRQn, 5, 0);
  HAL_NVIC_EnableIRQ(DMA2_Stream5_IRQn);
  /* DMA2_Stream6_IRQn interrupt configuration */
  HAL_NVIC_SetPriority(DMA2_Stream6_IRQn, 5, 0);
  HAL_NVIC_EnableIRQ(DMA2_Stream6_IRQn);

}

/* FMC initialization function */
static void MX_FMC_Init(void)
{

  FMC_SDRAM_TimingTypeDef SdramTiming = {0};

  /** Perform the SDRAM1 memory initialization sequence
  */
  hsdram1.Instance = FMC_SDRAM_DEVICE;
  /* hsdram1.Init */
  hsdram1.Init.SDBank = FMC_SDRAM_BANK1;
  hsdram1.Init.ColumnBitsNumber = FMC_SDRAM_COLUMN_BITS_NUM_8;
  hsdram1.Init.RowBitsNumber = FMC_SDRAM_ROW_BITS_NUM_12;
  hsdram1.Init.MemoryDataWidth = FMC_SDRAM_MEM_BUS_WIDTH_16;
  hsdram1.Init.InternalBankNumber = FMC_SDRAM_INTERN_BANKS_NUM_4;
  hsdram1.Init.CASLatency = FMC_SDRAM_CAS_LATENCY_3;
  hsdram1.Init.WriteProtection = FMC_SDRAM_WRITE_PROTECTION_DISABLE;
  hsdram1.Init.SDClockPeriod = FMC_SDRAM_CLOCK_PERIOD_2;
  hsdram1.Init.ReadBurst = FMC_SDRAM_RBURST_ENABLE;
  hsdram1.Init.ReadPipeDelay = FMC_SDRAM_RPIPE_DELAY_0;
  /* SdramTiming */
  SdramTiming.LoadToActiveDelay = 2;
  SdramTiming.ExitSelfRefreshDelay = 7;
  SdramTiming.SelfRefreshTime = 4;
  SdramTiming.RowCycleDelay = 7;
  SdramTiming.WriteRecoveryTime = 3;
  SdramTiming.RPDelay = 2;
  SdramTiming.RCDDelay = 2;

  if (HAL_SDRAM_Init(&hsdram1, &SdramTiming) != HAL_OK)
  {
    Error_Handler( );
  }

  /* USER CODE BEGIN FMC_Init 2 */
  __IO uint32_t tmpmrd = 0;

    /* Step 1: Configure a clock configuration enable command */
    Command.CommandMode            = FMC_SDRAM_CMD_CLK_ENABLE;
    Command.CommandTarget          =  FMC_SDRAM_CMD_TARGET_BANK1;
    Command.AutoRefreshNumber      = 1;
    Command.ModeRegisterDefinition = 0;

    /* Send the command */
    HAL_SDRAM_SendCommand(&hsdram1, &Command, SDRAM_TIMEOUT);

    /* Step 2: Insert 100 us minimum delay */
    /* Inserted delay is equal to 1 ms due to systick time base unit (ms) */
    HAL_Delay(1);

    /* Step 3: Configure a PALL (precharge all) command */
    Command.CommandMode            = FMC_SDRAM_CMD_PALL;
    Command.CommandTarget          = FMC_SDRAM_CMD_TARGET_BANK1;
    Command.AutoRefreshNumber      = 1;
    Command.ModeRegisterDefinition = 0;

    /* Send the command */
    HAL_SDRAM_SendCommand(&hsdram1, &Command, SDRAM_TIMEOUT);

    /* Step 4: Configure an Auto Refresh command */
    Command.CommandMode            = FMC_SDRAM_CMD_AUTOREFRESH_MODE;
    Command.CommandTarget          = FMC_SDRAM_CMD_TARGET_BANK1;
    Command.AutoRefreshNumber      = 8;
    Command.ModeRegisterDefinition = 0;

    /* Send the command */
    HAL_SDRAM_SendCommand(&hsdram1, &Command, SDRAM_TIMEOUT);

    /* Step 5: Program the external memory mode register */
    tmpmrd = (uint32_t)SDRAM_MODEREG_BURST_LENGTH_1 | \
             SDRAM_MODEREG_BURST_TYPE_SEQUENTIAL    | \
             SDRAM_MODEREG_CAS_LATENCY_3            | \
             SDRAM_MODEREG_OPERATING_MODE_STANDARD  | \
             SDRAM_MODEREG_WRITEBURST_MODE_SINGLE;

    Command.CommandMode            = FMC_SDRAM_CMD_LOAD_MODE;
    Command.CommandTarget          = FMC_SDRAM_CMD_TARGET_BANK1;
    Command.AutoRefreshNumber      = 1;
    Command.ModeRegisterDefinition = tmpmrd;

    /* Send the command */
    HAL_SDRAM_SendCommand(&hsdram1, &Command, SDRAM_TIMEOUT);

    /* Step 6: Set the refresh rate counter */
    /* Set the device refresh rate */
    HAL_SDRAM_ProgramRefreshRate(&hsdram1, REFRESH_COUNT);

    //Deactivate speculative/cache access to first FMC Bank to save FMC bandwidth
    FMC_Bank1->BTCR[0] = 0x000030D2;
  /* USER CODE END FMC_Init 2 */
}

static void MX_GPIO_Init(void)
{
  GPIO_InitTypeDef GPIO_InitStruct = {0};

  /* GPIO Ports Clock Enable */
  __HAL_RCC_GPIOE_CLK_ENABLE();
  __HAL_RCC_GPIOB_CLK_ENABLE();
  __HAL_RCC_GPIOC_CLK_ENABLE();
  __HAL_RCC_GPIOA_CLK_ENABLE();
  __HAL_RCC_GPIOG_CLK_ENABLE();
  __HAL_RCC_GPIOJ_CLK_ENABLE();
  __HAL_RCC_GPIOD_CLK_ENABLE();
  __HAL_RCC_GPIOK_CLK_ENABLE();
  __HAL_RCC_GPIOF_CLK_ENABLE();
  __HAL_RCC_GPIOI_CLK_ENABLE();
  __HAL_RCC_GPIOH_CLK_ENABLE();

  /*Configure GPIO pin Output Level */
  HAL_GPIO_WritePin(LCD_BL_CTRL_GPIO_Port, LCD_BL_CTRL_Pin, GPIO_PIN_SET);

  /*Configure GPIO pin Output Level */
  HAL_GPIO_WritePin(LCD_DISP_GPIO_Port, LCD_DISP_Pin, GPIO_PIN_SET);

  /*Configure GPIO pin : uSD_Pin */
  GPIO_InitStruct.Pin = uSD_Pin;
  GPIO_InitStruct.Mode = GPIO_MODE_INPUT;
  GPIO_InitStruct.Pull = GPIO_NOPULL;
  HAL_GPIO_Init(uSD_GPIO_Port, &GPIO_InitStruct);

  /*Configure GPIO pin : LCD_BL_CTRL_Pin */
  GPIO_InitStruct.Pin = LCD_BL_CTRL_Pin;
  GPIO_InitStruct.Mode = GPIO_MODE_OUTPUT_PP;
  GPIO_InitStruct.Pull = GPIO_NOPULL;
  GPIO_InitStruct.Speed = GPIO_SPEED_FREQ_LOW;
  HAL_GPIO_Init(LCD_BL_CTRL_GPIO_Port, &GPIO_InitStruct);

  /*Configure GPIO pin : LCD_DISP_Pin */
  GPIO_InitStruct.Pin = LCD_DISP_Pin;
  GPIO_InitStruct.Mode = GPIO_MODE_OUTPUT_PP;
  GPIO_InitStruct.Pull = GPIO_NOPULL;
  GPIO_InitStruct.Speed = GPIO_SPEED_FREQ_LOW;
  HAL_GPIO_Init(LCD_DISP_GPIO_Port, &GPIO_InitStruct);

}

/* USER CODE BEGIN 4 */

/*Przerwanie w przypadku zapełnienia bufora danych UART */
void HAL_UART_RxCpltCallback(UART_HandleTypeDef *huart) {
	if(huart->Instance == USART6){
		osSemaphoreRelease(UartsemHandle);
		memcpy(Received2, Received, GPSbufor);
		asdGPS[0]++;
		pomuart=0;
	}
}

/*Przerwanie w przypadku zapełnienia bufora danych SPI */
void HAL_SPI_RxCpltCallback(SPI_HandleTypeDef * hspi){
		osSemaphoreRelease(SPIsemHandle);
		asdUART1[0]++;
		memcpy(Received431, Received4, SPIbufor);
		osSemaphoreRelease(SPIzapHandle);
}

/* USER CODE END 4 */

__weak void TouchGFX_Task(void *argument)
{
  /* USER CODE BEGIN 5 */
  MX_TouchGFX_Process();
  /* Infinite loop */
  for(;;)
  {
    osDelay(1);
  }
  /* USER CODE END 5 */
}

void StartTask02(void *argument)
{
  /* USER CODE BEGIN StartTask02 */

  /* Infinite loop */
	  for(;;){
		  /*funkcja odpowiedzialna za czyszczenie i wyrejestrowanie zarejestrowanego obszar roboczy woluminu */
		  if(zapisekran==0 && zapisdzial==1){
		  		zapisdzial=0;
		  		f_mount(&SDFatFS, (TCHAR const*)NULL, 0);
		  }
		  /*funkcja odpowiedzialna za rejestrowanie zarejestrowanego nowego obszaru roboczego woluminu */
		  if(zapisekran==1 && zapisdzial==0){
		  		if(f_mount(&SDFatFS, (TCHAR const*)SDPath, 0) == FR_OK){
		  			zapisdzial=1;
		  		}
		  }
		  /*funkcja odpowiedzalna za zapis odpowiednich danych do odpowiednich plików*/
		  if(zapisdzial!=0){
		  			int i;
		  			asdCZUJNIKI[1]++;
		  			/*tworzenie pliku jeżeli nie istnieje i/lub dopisanie danych na końcu pliku*/
		  			if(f_open(&SDFile, "DANEMPU.TXT", FA_OPEN_APPEND | FA_WRITE) == FR_OK){
						for(i = 0; i < licznik4; ++i){
							res = f_write(&SDFile, buffer[i], strlen((char *)buffer[i]), (void *)&byteswritten);
							if((byteswritten == 0) || (res == FR_OK)){
								asdCZUJNIKI[2]++;
							}
						}
					}
					f_close(&SDFile);
					if(asdUART1[0]!=asdUART1[1]){
						if(f_open(&SDFile, "DANEUART.TXT", FA_OPEN_APPEND | FA_WRITE) == FR_OK){
							res = f_write(&SDFile, Received431, SPIbufor, (void *)&byteswritten);
						   	if((byteswritten == 0) || (res == FR_OK)){
						   		asdUART1[2]++;
						   	}
						}
						f_close(&SDFile);
						asdUART1[1]=asdUART1[0];
					}
					osSemaphoreRelease(SPIzapHandle);
					if(asdGPS[0]!=asdGPS[1]){
						if(f_open(&SDFile, "DANEGPS.TXT", FA_OPEN_APPEND | FA_WRITE) == FR_OK){
			   					res = f_write(&SDFile, Received2,GPSbufor, (void *)&byteswritten);
			   					if((byteswritten == 0) || (res == FR_OK)){
			   						asdGPS[2]++;
			   					}
			   			}
			   			f_close(&SDFile);
			   			asdGPS[1]=asdGPS[0];
					}
		  	}
		  	 /*zerowanie licznika bufora danych */
			licznik4=0;
			osDelay(250);
	  	 }

  /* USER CODE END StartTask02 */
}

void StartTask03(void *argument)
{
  /* USER CODE BEGIN StartTask03 */
  /* Infinite loop */
  for(;;)
  {
	  	  	MPU6050_Read_All(&hi2c1,&MPU6050);
		  	MPU6050_Parsing_NoOffest(&MPU6050);
		  	/*zczytanie czasu systemowego */
			HAL_RTC_GetTime(&hrtc, &RtcTime, RTC_FORMAT_BIN);
			Milliseconds = ((RtcTime.SecondFraction-RtcTime.SubSeconds)/((float)RtcTime.SecondFraction+1) * 1000);
			HAL_RTC_GetDate(&hrtc, &RtcDate, RTC_FORMAT_BIN);
		  	sprintf((char*)Message, "Time: %02d:%02d:%02d:%03d", RtcTime.Hours, RtcTime.Minutes, RtcTime.Seconds, Milliseconds);
		    /*konwesja floaut na long int (konwersja za pośrednictwem sprintf powoduje HardFault)*/
		  	dod1=(long int)10000*TempDH;
			dod2=(long int)10000*WilgDH;
			dod3=(long int)10000*TempBMP;
			/*wykrycie awarii I2C i jej usunięcie*/
			if(CisnBMP<90000 || CisnBMP>110000){
						awaria++;
						if(awaria>1){
							HAL_I2C_DeInit(&hi2c1);
							HAL_I2C_Init(&hi2c1);
							awaria=0;
							MPU6050_Init(&hi2c1, 1, 1, 5);
							MPU6050_Bypass(&hi2c1);
							HMC5883L_Setup(&hi2c1);
							MPU6050_Master(&hi2c1);
							MPU6050_Slave_Read(&hi2c1);
							BMP180_Init(&hi2c1,BMP180_STANDARD);
							osDelay(500);
						}
			}
			else{
				sprintf((char*)buffer[licznik4], "%s;%i;%i;%i;%i;%i;%i;%ld;%ld;%ld;%ld;%i;%i;%i\n", Message,MPU6050.Accel_X_RAW,MPU6050.Accel_Y_RAW,MPU6050.Accel_Z_RAW,MPU6050.Gyro_X_RAW,MPU6050.Gyro_Y_RAW,MPU6050.Gyro_Z_RAW,dod1,dod2,dod3,CisnBMP,MPU6050.Mag_X_RAW,MPU6050.Mag_Y_RAW,MPU6050.Mag_Z_RAW);
				licznik4++;
			}
		  osDelay(5);
  }
  /* USER CODE END StartTask03 */
}

void StartTask04(void *argument)
{
  /* USER CODE BEGIN StartTask04 */

  /* Infinite loop */
  for(;;)
  {
	  /*wywyołanie UART_Receive_IT*/
	  osSemaphoreAcquire(UartsemHandle, portMAX_DELAY);
	  Received[0]=0;
	  Received[1]=0;
	  HAL_UART_Receive_IT(&huart6, Received, GPSbufor);
  }
  /* USER CODE END StartTask04 */
}

void StartTask05(void *argument)
{
  /* USER CODE BEGIN StartTask05 */
  /* Infinite loop */
	osDelay(3000);
	HAL_TIM_Base_Start_IT(&htim14);
	for(;;)
	{
		TempBMP = BMP180_ReadTemperature();
		osDelay(1);
		CisnBMP = BMP180_ReadPressure();
		osDelay(1000);

  }
  /* USER CODE END StartTask05 */
}

void StartTask06(void *argument)
{
  /* USER CODE BEGIN StartTask06 */
  /* Infinite loop */
  for(;;)
  {
	  /*wykrycie błędu polegającym na odczytu tylko pierwszego bajtu transmisji*/
	  if(Received[1]==0){
		  osSemaphoreRelease(UartsemHandle);
		  HAL_UART_AbortReceive_IT(&huart6);
	  }
	  osDelay(1);
	  pomuart++;
	  if(pomuart>7000)
	  {
		  pomuart=0;
		  osSemaphoreRelease(UartsemHandle);
		  memcpy(Received2, Received, GPSbufor);
		  asdGPS[0]++;
		  pomuart=0;
	  }
	  pomuart++;
	  osDelay(1);
  }
  /* USER CODE END StartTask06 */
}

void StartTask07(void *argument)
{
  /* USER CODE BEGIN StartTask07 */
  /* Infinite loop */
  for(;;)
  {
	  /*wywyołanie SPI_Receive_DMA*/
	  osSemaphoreAcquire(SPIsemHandle, portMAX_DELAY);
	  HAL_SPI_Receive_DMA(&hspi5,Received4, SPIbufor);
  }
  /* USER CODE END StartTask07 */
}

/* MPU Configuration */

void MPU_Config(void)
{
  MPU_Region_InitTypeDef MPU_InitStruct = {0};

  /* Disables the MPU */
  HAL_MPU_Disable();
  /** Initializes and configures the Region and the memory to be protected
  */
  MPU_InitStruct.Enable = MPU_REGION_ENABLE;
  MPU_InitStruct.Number = MPU_REGION_NUMBER0;
  MPU_InitStruct.BaseAddress = 0x00000000;
  MPU_InitStruct.Size = MPU_REGION_SIZE_256MB;
  MPU_InitStruct.SubRegionDisable = 0x0;
  MPU_InitStruct.TypeExtField = MPU_TEX_LEVEL0;
  MPU_InitStruct.AccessPermission = MPU_REGION_FULL_ACCESS;
  MPU_InitStruct.DisableExec = MPU_INSTRUCTION_ACCESS_ENABLE;
  MPU_InitStruct.IsShareable = MPU_ACCESS_NOT_SHAREABLE;
  MPU_InitStruct.IsCacheable = MPU_ACCESS_NOT_CACHEABLE;
  MPU_InitStruct.IsBufferable = MPU_ACCESS_NOT_BUFFERABLE;

  HAL_MPU_ConfigRegion(&MPU_InitStruct);
  /** Initializes and configures the Region and the memory to be protected
  */
  MPU_InitStruct.Enable = MPU_REGION_ENABLE;
  MPU_InitStruct.Number = MPU_REGION_NUMBER1;
  MPU_InitStruct.BaseAddress = 0x90000000;
  MPU_InitStruct.Size = MPU_REGION_SIZE_16MB;
  MPU_InitStruct.SubRegionDisable = 0x0;
  MPU_InitStruct.TypeExtField = MPU_TEX_LEVEL0;
  MPU_InitStruct.AccessPermission = MPU_REGION_FULL_ACCESS;
  MPU_InitStruct.DisableExec = MPU_INSTRUCTION_ACCESS_ENABLE;
  MPU_InitStruct.IsShareable = MPU_ACCESS_NOT_SHAREABLE;
  MPU_InitStruct.IsCacheable = MPU_ACCESS_CACHEABLE;
  MPU_InitStruct.IsBufferable = MPU_ACCESS_NOT_BUFFERABLE;

  HAL_MPU_ConfigRegion(&MPU_InitStruct);
  /* Enables the MPU */
  HAL_MPU_Enable(MPU_PRIVILEGED_DEFAULT);

}
void HAL_TIM_PeriodElapsedCallback(TIM_HandleTypeDef *htim)
{
  if (htim->Instance == TIM6) {
    HAL_IncTick();
  }
  /* USER CODE BEGIN Callback 1 */
	if(htim->Instance == TIM14){
	  	  DHT_GetData(&DHT11_Data);
	  	  TempDH = DHT11_Data.Temperature;
	  	  WilgDH = DHT11_Data.Humidity;
	  	  asdCZUJNIKI[0]++;
	}
  /* USER CODE END Callback 1 */
}

void Error_Handler(void)
{
}

/************************ (C) COPYRIGHT STMicroelectronics *****END OF FILE****/

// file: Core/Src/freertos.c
/* USER CODE BEGIN Header */
/**
  ******************************************************************************
  * File Name          : freertos.c
  * Description        : Code for freertos applications
  ******************************************************************************
  * @attention
  *
  * <h2><center>&copy; Copyright (c) 2020 STMicroelectronics.
  * All rights reserved.</center></h2>
  *
  * This software component is licensed by ST under Ultimate Liberty license
  * SLA0044, the "License"; You may not use this file except in compliance with
  * the License. You may obtain a copy of the License at:
  *                             www.st.com/SLA0044
  *
  ******************************************************************************
  */
/* USER CODE END Header */

#include "FreeRTOS.h"
#include "task.h"
#include "main.h"

/* USER CODE BEGIN FunctionPrototypes */
extern portBASE_TYPE IdleTaskHook(void* p);
/* USER CODE END FunctionPrototypes */

/* Hook prototypes */
void vApplicationIdleHook(void);
void vApplicationStackOverflowHook(xTaskHandle xTask, signed char *pcTaskName);

/* USER CODE BEGIN 2 */
void vApplicationIdleHook( void )
{
   /* vApplicationIdleHook() will only be called if configUSE_IDLE_HOOK is set
   to 1 in FreeRTOSConfig.h. It will be called on each iteration of the idle
   task. It is essential that code added to this hook function never attempts
   to block in any way (for example, call xQueueReceive() with a block time
   specified, or call vTaskDelay()). If the application makes use of the
   vTaskDelete() API function (as this demo application does) then it is also
   important that vApplicationIdleHook() is permitted to return to its calling
   function, because it is the responsibility of the idle task to clean up
   memory allocated by the kernel to any task that has since been deleted. */
   vTaskSetApplicationTaskTag(NULL, IdleTaskHook);
}
/* USER CODE END 2 */

/* USER CODE BEGIN 4 */
void vApplicationStackOverflowHook(xTaskHandle xTask, signed char *pcTaskName)
{
   /* Run time stack overflow checking is performed if
   configCHECK_FOR_STACK_OVERFLOW is defined to 1 or 2. This hook function is
   called if a stack overflow is detected. */
}
/* USER CODE END 4 */

/************************ (C) COPYRIGHT STMicroelectronics *****END OF FILE****/
